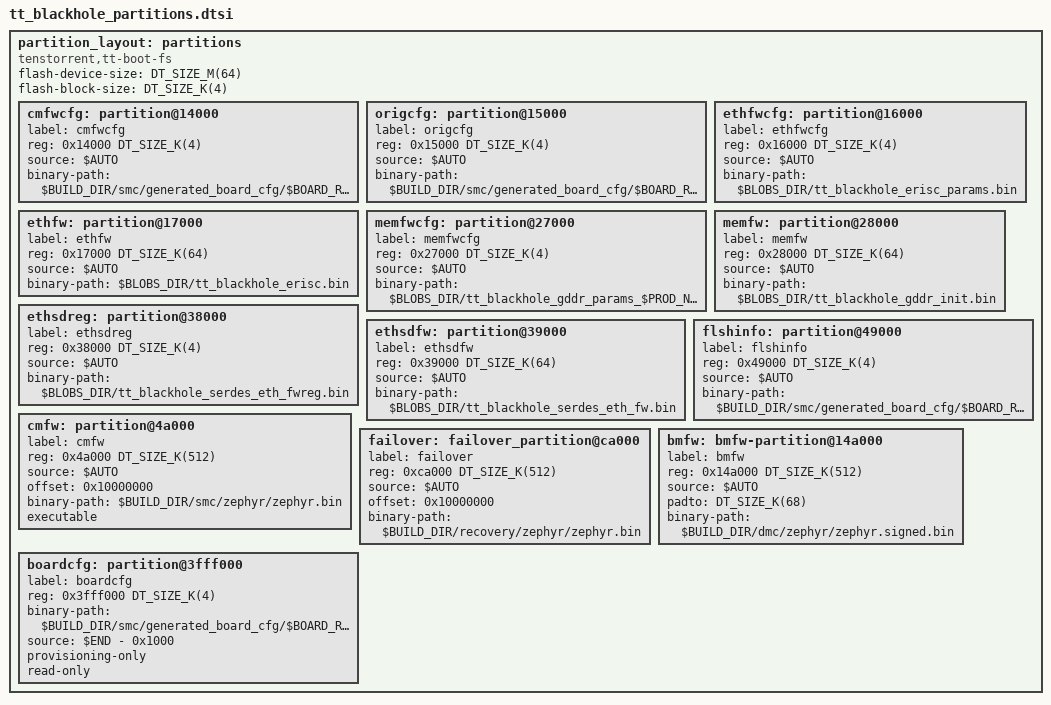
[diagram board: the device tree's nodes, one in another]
/*
 * Copyright (c) 2025 Tenstorrent AI ULC
 *
 * SPDX-License-Identifier: Apache-2.0
 */

#include <mem.h>

partition_layout: partitions {
	compatible = "tenstorrent,tt-boot-fs", "fixed-partitions";
	#address-cells = <1>;
	#size-cells = <1>;

	flash-device-size = <DT_SIZE_M(64)>;
	flash-block-size = <DT_SIZE_K(4)>;

	cmfwcfg: partition@14000 {
		label = "cmfwcfg";
		reg = <0x14000 DT_SIZE_K(4)>;
		source = "$AUTO";
		binary-path = "$BUILD_DIR/smc/generated_board_cfg/$BOARD_REV/fw_table.bin";
	};

	origcfg: partition@15000 {
		label = "origcfg";
		reg = <0x15000 DT_SIZE_K(4)>;
		source = "$AUTO";
		binary-path = "$BUILD_DIR/smc/generated_board_cfg/$BOARD_REV/fw_table.bin";
	};

	ethfwcfg: partition@16000 {
		label = "ethfwcfg";
		reg = <0x16000 DT_SIZE_K(4)>;
		source = "$AUTO";
		binary-path = "$BLOBS_DIR/tt_blackhole_erisc_params.bin";
	};

	ethfw: partition@17000 {
		label = "ethfw";
		reg = <0x17000 DT_SIZE_K(64)>;
		source = "$AUTO";
		binary-path = "$BLOBS_DIR/tt_blackhole_erisc.bin";
	};

	memfwcfg: partition@27000 {
		label = "memfwcfg";
		reg = <0x27000 DT_SIZE_K(4)>;
		source = "$AUTO";
		binary-path = "$BLOBS_DIR/tt_blackhole_gddr_params_$PROD_NAME.bin";
	};

	memfw: partition@28000 {
		label = "memfw";
		reg = <0x28000 DT_SIZE_K(64)>;
		source = "$AUTO";
		binary-path = "$BLOBS_DIR/tt_blackhole_gddr_init.bin";
	};

	ethsdreg: partition@38000 {
		label = "ethsdreg";
		reg = <0x38000 DT_SIZE_K(4)>;
		source = "$AUTO";
		binary-path = "$BLOBS_DIR/tt_blackhole_serdes_eth_fwreg.bin";
	};

	ethsdfw: partition@39000 {
		label = "ethsdfw";
		reg = <0x39000 DT_SIZE_K(64)>;
		source = "$AUTO";
		binary-path = "$BLOBS_DIR/tt_blackhole_serdes_eth_fw.bin";
	};

	flshinfo: partition@49000 {
		label = "flshinfo";
		reg = <0x49000 DT_SIZE_K(4)>;
		source = "$AUTO";
		binary-path =
			"$BUILD_DIR/smc/generated_board_cfg/$BOARD_REV/flash_info.bin";
	};

	cmfw: partition@4a000 {
		label = "cmfw";
		reg = <0x4a000 DT_SIZE_K(512)>;
		source = "$AUTO";
		offset = <0x10000000>;
		binary-path = "$BUILD_DIR/smc/zephyr/zephyr.bin";
		executable;
	};

	failover: failover_partition@ca000 {
		label = "failover";
		reg = <0xca000 DT_SIZE_K(512)>;
		source = "$AUTO";
		offset = <0x10000000>;
		binary-path = "$BUILD_DIR/recovery/zephyr/zephyr.bin";
	};

	bmfw: bmfw-partition@14a000 {
		label = "bmfw";
		reg = <0x14a000 DT_SIZE_K(512)>;
		source = "$AUTO";
		padto = <DT_SIZE_K(68)>;
		binary-path = "$BUILD_DIR/dmc/zephyr/zephyr.signed.bin";
	};

	boardcfg: partition@3fff000 {
		label = "boardcfg";
		reg = <0x3fff000 DT_SIZE_K(4)>;
		binary-path = "$BUILD_DIR/smc/generated_board_cfg/$BOARD_REV/read_only.bin";
		/* Always placed 4KB from end of flash */
		source = "$END - 0x1000";
		provisioning-only;
		read-only;
	};
};
